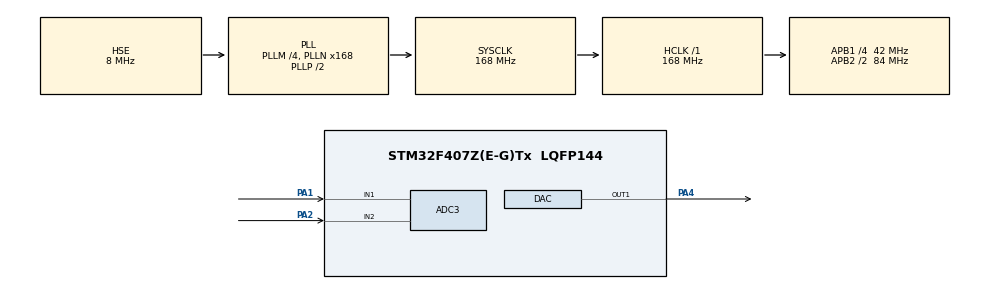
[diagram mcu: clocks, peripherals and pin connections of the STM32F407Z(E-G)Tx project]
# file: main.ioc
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ADC3.Channel-0\#ChannelRegularConversion=ADC_CHANNEL_1
ADC3.Channel-2\#ChannelRegularConversion=ADC_CHANNEL_2
ADC3.ClockPrescaler=ADC_CLOCK_SYNC_PCLK_DIV8
ADC3.ContinuousConvMode=ENABLE
ADC3.DMAContinuousRequests=ENABLE
ADC3.ExternalTrigConv=ADC_SOFTWARE_START
ADC3.NbrOfConversion=2
ADC3.NbrOfConversionFlag=1
ADC3.Rank-0\#ChannelRegularConversion=1
ADC3.Rank-2\#ChannelRegularConversion=2
ADC3.SamplingTime-0\#ChannelRegularConversion=ADC_SAMPLETIME_3CYCLES
ADC3.SamplingTime-2\#ChannelRegularConversion=ADC_SAMPLETIME_28CYCLES
ADC3.ScanConvMode=ENABLE
DAC.DAC_Trigger=DAC_TRIGGER_T2_TRGO
Dma.ADC3.1.Direction=DMA_PERIPH_TO_MEMORY
Dma.ADC3.1.FIFOMode=DMA_FIFOMODE_DISABLE
Dma.ADC3.1.Instance=DMA2_Stream0
Dma.ADC3.1.MemDataAlignment=DMA_MDATAALIGN_HALFWORD
Dma.ADC3.1.MemInc=DMA_MINC_ENABLE
Dma.ADC3.1.Mode=DMA_CIRCULAR
Dma.ADC3.1.PeriphDataAlignment=DMA_PDATAALIGN_HALFWORD
Dma.ADC3.1.PeriphInc=DMA_PINC_DISABLE
Dma.ADC3.1.Priority=DMA_PRIORITY_LOW
Dma.DAC1.0.Direction=DMA_MEMORY_TO_PERIPH
Dma.DAC1.0.FIFOMode=DMA_FIFOMODE_DISABLE
Dma.DAC1.0.Instance=DMA1_Stream5
Dma.DAC1.0.MemDataAlignment=DMA_MDATAALIGN_HALFWORD
Dma.DAC1.0.MemInc=DMA_MINC_ENABLE
Dma.DAC1.0.Mode=DMA_CIRCULAR
Dma.DAC1.0.PeriphDataAlignment=DMA_PDATAALIGN_HALFWORD
Dma.DAC1.0.PeriphInc=DMA_PINC_DISABLE
Dma.DAC1.0.Priority=DMA_PRIORITY_LOW
Dma.Request0=DAC1
Dma.Request1=ADC3
Mcu.Family=STM32F4
Mcu.Name=STM32F407Z(E-G)Tx
Mcu.Package=LQFP144
NVIC.DMA1_Stream5_IRQn=true\:0\:0\:false\:false\:true\:false\:true\:true
NVIC.DMA2_Stream0_IRQn=true\:0\:0\:false\:false\:true\:false\:true\:true
NVIC.PriorityGroup=NVIC_PRIORITYGROUP_4
NVIC.TIM2_IRQn=true\:0\:0\:true\:false\:true\:true\:true\:true
NVIC.TIM4_IRQn=true\:0\:0\:true\:false\:true\:true\:true\:true
PA1.Signal=ADCx_IN1
PA13.Mode=Serial_Wire
PA13.Signal=SYS_JTMS-SWDIO
PA14.Mode=Serial_Wire
PA14.Signal=SYS_JTCK-SWCLK
PA2.Signal=ADCx_IN2
PA4.Signal=COMP_DAC1_group
PH0-OSC_IN.Mode=HSE-External-Oscillator
PH0-OSC_IN.Signal=RCC_OSC_IN
PH1-OSC_OUT.Mode=HSE-External-Oscillator
PH1-OSC_OUT.Signal=RCC_OSC_OUT
ProjectManager.HeapSize=0x200
ProjectManager.StackSize=0x400
ProjectManager.TargetToolchain=STM32CubeIDE
RCC.48MHZClocksFreq_Value=84000000
RCC.AHBFreq_Value=168000000
RCC.APB1CLKDivider=RCC_HCLK_DIV4
RCC.APB1Freq_Value=42000000
RCC.APB1TimFreq_Value=84000000
RCC.APB2CLKDivider=RCC_HCLK_DIV2
RCC.APB2Freq_Value=84000000
RCC.APB2TimFreq_Value=168000000
RCC.CortexFreq_Value=168000000
RCC.HCLKFreq_Value=168000000
RCC.HSE_VALUE=8000000
RCC.HSI_VALUE=16000000
RCC.LSE_VALUE=32768
RCC.PLLM=4
RCC.PLLN=168
RCC.PLLSourceVirtual=RCC_PLLSOURCE_HSE
RCC.SYSCLKFreq_VALUE=168000000
RCC.SYSCLKSource=RCC_SYSCLKSOURCE_PLLCLK
RCC.VCOOutputFreq_Value=336000000
SH.ADCx_IN1.0=ADC3_IN1,IN1
SH.ADCx_IN2.0=ADC3_IN2,IN2
SH.COMP_DAC1_group.0=DAC_OUT1,DAC_OUT1
TIM2.CounterMode=TIM_COUNTERMODE_UP
TIM2.Period=1000-1
TIM2.Prescaler=84-1
TIM2.TIM_MasterOutputTrigger=TIM_TRGO_UPDATE
TIM4.Period=1000-1
TIM4.Prescaler=84-1
VP_TIM2_VS_ClockSourceINT.Mode=Internal
VP_TIM4_VS_ClockSourceINT.Mode=Internal
board=custom

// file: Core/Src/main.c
/* USER CODE BEGIN Header */
/**
  ******************************************************************************
  * @file           : main.c
  * @brief          : Main program body
  ******************************************************************************
  * @attention
  *
  * Copyright (c) 2024 STMicroelectronics.
  * All rights reserved.
  *
  * This software is licensed under terms that can be found in the LICENSE file
  * in the root directory of this software component.
  * If no LICENSE file comes with this software, it is provided AS-IS.
  *
  ******************************************************************************
  */
/* USER CODE END Header */
#include "main.h"

/* USER CODE BEGIN Includes */
#include "math.h"
#define ARM_MATH_CM4
#include "arm_math.h"
/* USER CODE END Includes */

/* USER CODE BEGIN PD */
#define SAMPLES 1000
/* USER CODE END PD */

ADC_HandleTypeDef hadc3;
DMA_HandleTypeDef hdma_adc3;

DAC_HandleTypeDef hdac;
DMA_HandleTypeDef hdma_dac1;

TIM_HandleTypeDef htim2;
TIM_HandleTypeDef htim4;

/* USER CODE BEGIN PV */
uint16_t dac_buff[SAMPLES];
uint16_t dac_val = 0;
uint16_t adc_dma[2];

// INPUT SIGNAL VARIABLES
//uint16_t freq[] = {1000, 500, 200, 100, 50, 20, 10};
uint16_t freq[] = 	{1,    2,   5,   10,  20, 50, 100}; // Hz
size_t freq_len = 0;
int freq_i = 0;
uint16_t frequency = 1;
const uint32_t PERIODS = 4;
const uint32_t COUNTS_PER_PERIOD = PERIODS*SAMPLES;
uint32_t count = 0;

// SECOND ORDER IRR BUTTERWORTH FILTER
#define BLOCK_SIZE 1
#define N_STAGES 1
float32_t x[BLOCK_SIZE] = { 0 }, y[BLOCK_SIZE] = { 0 }; // input, output
float32_t f_states[4*N_STAGES] = { 0 };
float32_t coeff[] = { 0.020083, 0.040167, 0.020083, 1.561018, -0.641352 }; // obtained via MATLAB/Octave script
arm_biquad_casd_df1_inst_f32 s1;

/* USER CODE END PV */

void SystemClock_Config(void);
static void MX_GPIO_Init(void);
static void MX_DMA_Init(void);
static void MX_DAC_Init(void);
static void MX_TIM2_Init(void);
static void MX_ADC3_Init(void);
static void MX_TIM4_Init(void);

int main(void)
{

  /* USER CODE BEGIN 1 */
  for (int i = 0; i < SAMPLES; i++)
		dac_buff[i] = (uint32_t)( 0.9f*( sin(i*(2*M_PI/SAMPLES)) + 1.1f)*(( 0xfff )/2) );
  freq_len = sizeof(freq)/sizeof(freq[0]);
  arm_biquad_cascade_df1_init_f32(&s1, (uint8_t)N_STAGES, coeff, f_states);
  /* USER CODE END 1 */

  /* MCU Configuration--------------------------------------------------------*/

  /* Reset of all peripherals, Initializes the Flash interface and the Systick. */
  HAL_Init();

  /* Configure the system clock */
  SystemClock_Config();

  /* Initialize all configured peripherals */
  MX_GPIO_Init();
  MX_DMA_Init();
  MX_DAC_Init();
  MX_TIM2_Init();
  MX_ADC3_Init();
  MX_TIM4_Init();
  /* USER CODE BEGIN 2 */
  HAL_TIM_Base_Start_IT(&htim2);
  HAL_TIM_Base_Start_IT(&htim4);
  HAL_DAC_Start_DMA(&hdac, DAC_CHANNEL_1, (uint32_t *)&dac_buff, SAMPLES, DAC_ALIGN_12B_R);
  HAL_ADC_Start_DMA(&hadc3, (uint32_t *)&adc_dma, 2);
  /* USER CODE END 2 */

  /* Infinite loop */
  while (1)
  {

  }
}

void SystemClock_Config(void)
{
  RCC_OscInitTypeDef RCC_OscInitStruct = {0};
  RCC_ClkInitTypeDef RCC_ClkInitStruct = {0};

  /** Configure the main internal regulator output voltage
  */
  __HAL_RCC_PWR_CLK_ENABLE();
  __HAL_PWR_VOLTAGESCALING_CONFIG(PWR_REGULATOR_VOLTAGE_SCALE1);

  /** Initializes the RCC Oscillators according to the specified parameters
  * in the RCC_OscInitTypeDef structure.
  */
  RCC_OscInitStruct.OscillatorType = RCC_OSCILLATORTYPE_HSE;
  RCC_OscInitStruct.HSEState = RCC_HSE_ON;
  RCC_OscInitStruct.PLL.PLLState = RCC_PLL_ON;
  RCC_OscInitStruct.PLL.PLLSource = RCC_PLLSOURCE_HSE;
  RCC_OscInitStruct.PLL.PLLM = 4;
  RCC_OscInitStruct.PLL.PLLN = 168;
  RCC_OscInitStruct.PLL.PLLP = RCC_PLLP_DIV2;
  RCC_OscInitStruct.PLL.PLLQ = 4;
  if (HAL_RCC_OscConfig(&RCC_OscInitStruct) != HAL_OK)
  {
    Error_Handler();
  }

  /** Initializes the CPU, AHB and APB buses clocks
  */
  RCC_ClkInitStruct.ClockType = RCC_CLOCKTYPE_HCLK|RCC_CLOCKTYPE_SYSCLK
                              |RCC_CLOCKTYPE_PCLK1|RCC_CLOCKTYPE_PCLK2;
  RCC_ClkInitStruct.SYSCLKSource = RCC_SYSCLKSOURCE_PLLCLK;
  RCC_ClkInitStruct.AHBCLKDivider = RCC_SYSCLK_DIV1;
  RCC_ClkInitStruct.APB1CLKDivider = RCC_HCLK_DIV4;
  RCC_ClkInitStruct.APB2CLKDivider = RCC_HCLK_DIV2;

  if (HAL_RCC_ClockConfig(&RCC_ClkInitStruct, FLASH_LATENCY_5) != HAL_OK)
  {
    Error_Handler();
  }
}

static void MX_ADC3_Init(void)
{

  ADC_ChannelConfTypeDef sConfig = {0};

  /** Configure the global features of the ADC (Clock, Resolution, Data Alignment and number of conversion)
  */
  hadc3.Instance = ADC3;
  hadc3.Init.ClockPrescaler = ADC_CLOCK_SYNC_PCLK_DIV8;
  hadc3.Init.Resolution = ADC_RESOLUTION_12B;
  hadc3.Init.ScanConvMode = ENABLE;
  hadc3.Init.ContinuousConvMode = ENABLE;
  hadc3.Init.DiscontinuousConvMode = DISABLE;
  hadc3.Init.ExternalTrigConvEdge = ADC_EXTERNALTRIGCONVEDGE_NONE;
  hadc3.Init.ExternalTrigConv = ADC_SOFTWARE_START;
  hadc3.Init.DataAlign = ADC_DATAALIGN_RIGHT;
  hadc3.Init.NbrOfConversion = 2;
  hadc3.Init.DMAContinuousRequests = ENABLE;
  hadc3.Init.EOCSelection = ADC_EOC_SINGLE_CONV;
  if (HAL_ADC_Init(&hadc3) != HAL_OK)
  {
    Error_Handler();
  }

  /** Configure for the selected ADC regular channel its corresponding rank in the sequencer and its sample time.
  */
  sConfig.Channel = ADC_CHANNEL_1;
  sConfig.Rank = 1;
  sConfig.SamplingTime = ADC_SAMPLETIME_3CYCLES;
  if (HAL_ADC_ConfigChannel(&hadc3, &sConfig) != HAL_OK)
  {
    Error_Handler();
  }

  /** Configure for the selected ADC regular channel its corresponding rank in the sequencer and its sample time.
  */
  sConfig.Channel = ADC_CHANNEL_2;
  sConfig.Rank = 2;
  sConfig.SamplingTime = ADC_SAMPLETIME_28CYCLES;
  if (HAL_ADC_ConfigChannel(&hadc3, &sConfig) != HAL_OK)
  {
    Error_Handler();
  }

}

static void MX_DAC_Init(void)
{

  DAC_ChannelConfTypeDef sConfig = {0};

  /** DAC Initialization
  */
  hdac.Instance = DAC;
  if (HAL_DAC_Init(&hdac) != HAL_OK)
  {
    Error_Handler();
  }

  /** DAC channel OUT1 config
  */
  sConfig.DAC_Trigger = DAC_TRIGGER_T2_TRGO;
  sConfig.DAC_OutputBuffer = DAC_OUTPUTBUFFER_ENABLE;
  if (HAL_DAC_ConfigChannel(&hdac, &sConfig, DAC_CHANNEL_1) != HAL_OK)
  {
    Error_Handler();
  }

}

static void MX_TIM2_Init(void)
{

  TIM_ClockConfigTypeDef sClockSourceConfig = {0};
  TIM_MasterConfigTypeDef sMasterConfig = {0};

  htim2.Instance = TIM2;
  htim2.Init.Prescaler = 84-1;
  htim2.Init.CounterMode = TIM_COUNTERMODE_UP;
  htim2.Init.Period = 1000-1;
  htim2.Init.ClockDivision = TIM_CLOCKDIVISION_DIV1;
  htim2.Init.AutoReloadPreload = TIM_AUTORELOAD_PRELOAD_DISABLE;
  if (HAL_TIM_Base_Init(&htim2) != HAL_OK)
  {
    Error_Handler();
  }
  sClockSourceConfig.ClockSource = TIM_CLOCKSOURCE_INTERNAL;
  if (HAL_TIM_ConfigClockSource(&htim2, &sClockSourceConfig) != HAL_OK)
  {
    Error_Handler();
  }
  sMasterConfig.MasterOutputTrigger = TIM_TRGO_UPDATE;
  sMasterConfig.MasterSlaveMode = TIM_MASTERSLAVEMODE_DISABLE;
  if (HAL_TIMEx_MasterConfigSynchronization(&htim2, &sMasterConfig) != HAL_OK)
  {
    Error_Handler();
  }

}

static void MX_TIM4_Init(void)
{

  TIM_ClockConfigTypeDef sClockSourceConfig = {0};
  TIM_MasterConfigTypeDef sMasterConfig = {0};

  htim4.Instance = TIM4;
  htim4.Init.Prescaler = 84-1;
  htim4.Init.CounterMode = TIM_COUNTERMODE_UP;
  htim4.Init.Period = 1000-1;
  htim4.Init.ClockDivision = TIM_CLOCKDIVISION_DIV1;
  htim4.Init.AutoReloadPreload = TIM_AUTORELOAD_PRELOAD_DISABLE;
  if (HAL_TIM_Base_Init(&htim4) != HAL_OK)
  {
    Error_Handler();
  }
  sClockSourceConfig.ClockSource = TIM_CLOCKSOURCE_INTERNAL;
  if (HAL_TIM_ConfigClockSource(&htim4, &sClockSourceConfig) != HAL_OK)
  {
    Error_Handler();
  }
  sMasterConfig.MasterOutputTrigger = TIM_TRGO_RESET;
  sMasterConfig.MasterSlaveMode = TIM_MASTERSLAVEMODE_DISABLE;
  if (HAL_TIMEx_MasterConfigSynchronization(&htim4, &sMasterConfig) != HAL_OK)
  {
    Error_Handler();
  }

}

static void MX_DMA_Init(void)
{

  /* DMA controller clock enable */
  __HAL_RCC_DMA1_CLK_ENABLE();
  __HAL_RCC_DMA2_CLK_ENABLE();

  /* DMA interrupt init */
  /* DMA1_Stream5_IRQn interrupt configuration */
  HAL_NVIC_SetPriority(DMA1_Stream5_IRQn, 0, 0);
  HAL_NVIC_EnableIRQ(DMA1_Stream5_IRQn);
  /* DMA2_Stream0_IRQn interrupt configuration */
  HAL_NVIC_SetPriority(DMA2_Stream0_IRQn, 0, 0);
  HAL_NVIC_EnableIRQ(DMA2_Stream0_IRQn);

}

static void MX_GPIO_Init(void)
{

  /* GPIO Ports Clock Enable */
  __HAL_RCC_GPIOH_CLK_ENABLE();
  __HAL_RCC_GPIOA_CLK_ENABLE();

}

/* USER CODE BEGIN 4 */
void HAL_TIM_PeriodElapsedCallback(TIM_HandleTypeDef *htim)
{
	// VARYING DAC FREQUENCY
	// =============================================================================
	if (htim->Instance == TIM2) {
		x[0] = (float32_t) adc_dma[1];
		dac_val = HAL_DAC_GetValue(&hdac, DAC_CHANNEL_1);
		count++;
		if (count >= COUNTS_PER_PERIOD) {
			count = 0;
			freq_i++;
			if (freq_i >= (int)freq_len) {
				freq_i = 0;
			}
			__HAL_TIM_SET_AUTORELOAD(&htim2, (uint32_t)(1000/freq[freq_i]) - 1);
			frequency = freq[freq_i];
		}
	}
	// =============================================================================
	// PERFORMING IIR FILTER
	// =============================================================================
	if (htim->Instance == TIM4) {
		arm_biquad_cascade_df1_f32(&s1, x, y, (uint32_t)BLOCK_SIZE);
	}
	// =============================================================================
}

/* USER CODE END 4 */

void Error_Handler(void)
{
  __disable_irq();
  while (1)
  {
  }
}
